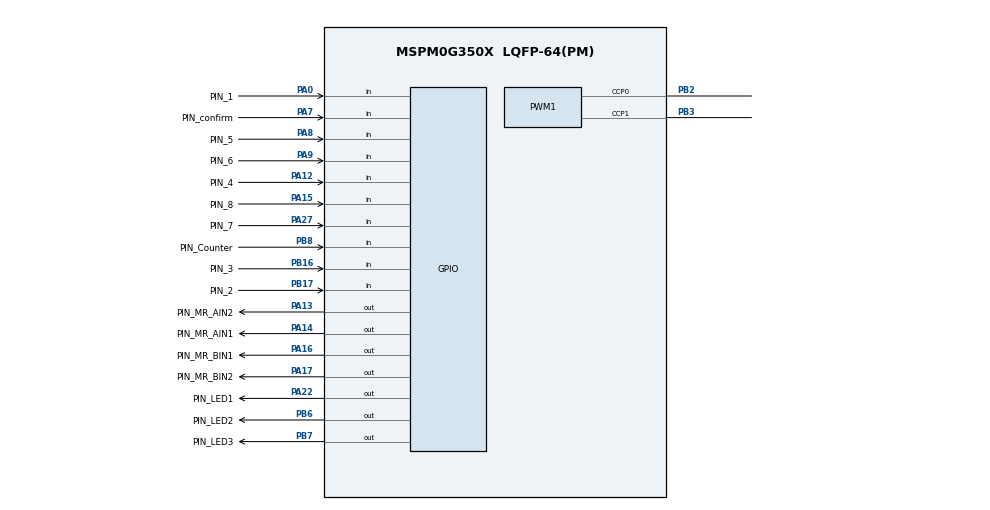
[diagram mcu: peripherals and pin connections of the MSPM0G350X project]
/**
 * @cliArgs --device "MSPM0G350X" --part "Default" --package "LQFP-64(PM)" --product "mspm0_sdk@2.05.01.00"
 * @versions {"tool":"1.24.0+4110"}
 */

/**
 * Import the modules used in this configuration.
 */
const GPIO    = scripting.addModule("/ti/driverlib/GPIO", {}, false);
const GPIO1   = GPIO.addInstance();
const GPIO2   = GPIO.addInstance();
const GPIO3   = GPIO.addInstance();
const GPIO4   = GPIO.addInstance();
const PWM     = scripting.addModule("/ti/driverlib/PWM", {}, false);
const PWM1    = PWM.addInstance();
const SYSCTL  = scripting.addModule("/ti/driverlib/SYSCTL");
const SYSTICK = scripting.addModule("/ti/driverlib/SYSTICK");
const TIMER   = scripting.addModule("/ti/driverlib/TIMER", {}, false);
const TIMER1  = TIMER.addInstance();

/**
 * Write custom configuration values to the imported modules.
 */
GPIO1.$name                         = "GPIO_GRP_XJ";
GPIO1.associatedPins.create(8);
GPIO1.associatedPins[0].$name       = "PIN_1";
GPIO1.associatedPins[0].direction   = "INPUT";
GPIO1.associatedPins[0].pin.$assign = "PA0";
GPIO1.associatedPins[1].$name       = "PIN_2";
GPIO1.associatedPins[1].direction   = "INPUT";
GPIO1.associatedPins[1].pin.$assign = "PB17";
GPIO1.associatedPins[2].$name       = "PIN_3";
GPIO1.associatedPins[2].direction   = "INPUT";
GPIO1.associatedPins[2].pin.$assign = "PB16";
GPIO1.associatedPins[3].$name       = "PIN_4";
GPIO1.associatedPins[3].direction   = "INPUT";
GPIO1.associatedPins[3].pin.$assign = "PA12";
GPIO1.associatedPins[4].$name       = "PIN_5";
GPIO1.associatedPins[4].direction   = "INPUT";
GPIO1.associatedPins[4].pin.$assign = "PA8";
GPIO1.associatedPins[5].$name       = "PIN_6";
GPIO1.associatedPins[5].direction   = "INPUT";
GPIO1.associatedPins[5].pin.$assign = "PA9";
GPIO1.associatedPins[6].$name       = "PIN_7";
GPIO1.associatedPins[6].direction   = "INPUT";
GPIO1.associatedPins[6].pin.$assign = "PA27";
GPIO1.associatedPins[7].$name       = "PIN_8";
GPIO1.associatedPins[7].direction   = "INPUT";
GPIO1.associatedPins[7].pin.$assign = "PA15";

const Board = scripting.addModule("/ti/driverlib/Board", {}, false);

GPIO2.$name                         = "GPIO_Motor";
GPIO2.associatedPins.create(4);
GPIO2.associatedPins[0].$name       = "PIN_MR_AIN1";
GPIO2.associatedPins[0].pin.$assign = "PA14";
GPIO2.associatedPins[1].$name       = "PIN_MR_AIN2";
GPIO2.associatedPins[1].pin.$assign = "PA13";
GPIO2.associatedPins[2].$name       = "PIN_MR_BIN1";
GPIO2.associatedPins[2].pin.$assign = "PA16";
GPIO2.associatedPins[3].$name       = "PIN_MR_BIN2";
GPIO2.associatedPins[3].pin.$assign = "PA17";

GPIO3.$name                               = "GPIO_GRP_Switch";
GPIO3.associatedPins.create(2);
GPIO3.associatedPins[0].$name             = "PIN_Counter";
GPIO3.associatedPins[0].internalResistor  = "PULL_UP";
GPIO3.associatedPins[0].interruptEn       = true;
GPIO3.associatedPins[0].polarity          = "FALL";
GPIO3.associatedPins[0].interruptPriority = "3";
GPIO3.associatedPins[0].direction         = "INPUT";
GPIO3.associatedPins[0].pin.$assign       = "PB8";
GPIO3.associatedPins[1].$name             = "PIN_confirm";
GPIO3.associatedPins[1].direction         = "INPUT";
GPIO3.associatedPins[1].internalResistor  = "PULL_UP";
GPIO3.associatedPins[1].interruptEn       = true;
GPIO3.associatedPins[1].polarity          = "FALL";
GPIO3.associatedPins[1].pin.$assign       = "PA7";

GPIO4.$name                          = "GPIO_GRP_LED";
GPIO4.associatedPins.create(3);
GPIO4.associatedPins[0].$name        = "PIN_LED1";
GPIO4.associatedPins[0].initialValue = "SET";
GPIO4.associatedPins[0].pin.$assign  = "PA22";
GPIO4.associatedPins[1].$name        = "PIN_LED2";
GPIO4.associatedPins[1].initialValue = "SET";
GPIO4.associatedPins[1].pin.$assign  = "PB6";
GPIO4.associatedPins[2].$name        = "PIN_LED3";
GPIO4.associatedPins[2].initialValue = "SET";
GPIO4.associatedPins[2].pin.$assign  = "PB7";

PWM1.$name                      = "PWM_0";
PWM1.timerCount                 = 32000;
PWM1.peripheral.ccp0Pin.$assign = "PB2";
PWM1.peripheral.ccp1Pin.$assign = "PB3";
PWM1.PWM_CHANNEL_0.$name        = "ti_driverlib_pwm_PWMTimerCC0";
PWM1.PWM_CHANNEL_1.$name        = "ti_driverlib_pwm_PWMTimerCC1";
PWM1.ccp0PinConfig.$name        = "ti_driverlib_gpio_GPIOPinGeneric0";
PWM1.ccp1PinConfig.$name        = "ti_driverlib_gpio_GPIOPinGeneric1";

SYSCTL.forceDefaultClkConfig = true;

SYSTICK.periodEnable      = true;
SYSTICK.period            = 32000;
SYSTICK.interruptEnable   = true;
SYSTICK.systickEnable     = true;
SYSTICK.interruptPriority = "0";

TIMER1.$name            = "TIMER_0";
TIMER1.timerClkPrescale = 256;
TIMER1.timerClkDiv      = 2;
TIMER1.timerMode        = "PERIODIC";
TIMER1.interrupts       = ["ZERO"];
TIMER1.timerPeriod      = "20ms";

/**
 * Pinmux solution for unlocked pins/peripherals. This ensures that minor changes to the automatic solver in a future
 * version of the tool will not impact the pinmux you originally saw.  These lines can be completely deleted in order to
 * re-solve from scratch.
 */
Board.peripheral.$suggestSolution          = "DEBUGSS";
Board.peripheral.swclkPin.$suggestSolution = "PA20";
Board.peripheral.swdioPin.$suggestSolution = "PA19";
PWM1.peripheral.$suggestSolution           = "TIMA1";
SYSCTL.peripheral.$suggestSolution         = "SYSCTL";
TIMER1.peripheral.$suggestSolution         = "TIMA0";
